AUTOSAR XML (schema 4-2-2)
package /STELLANTIS/EPT/ASWCs
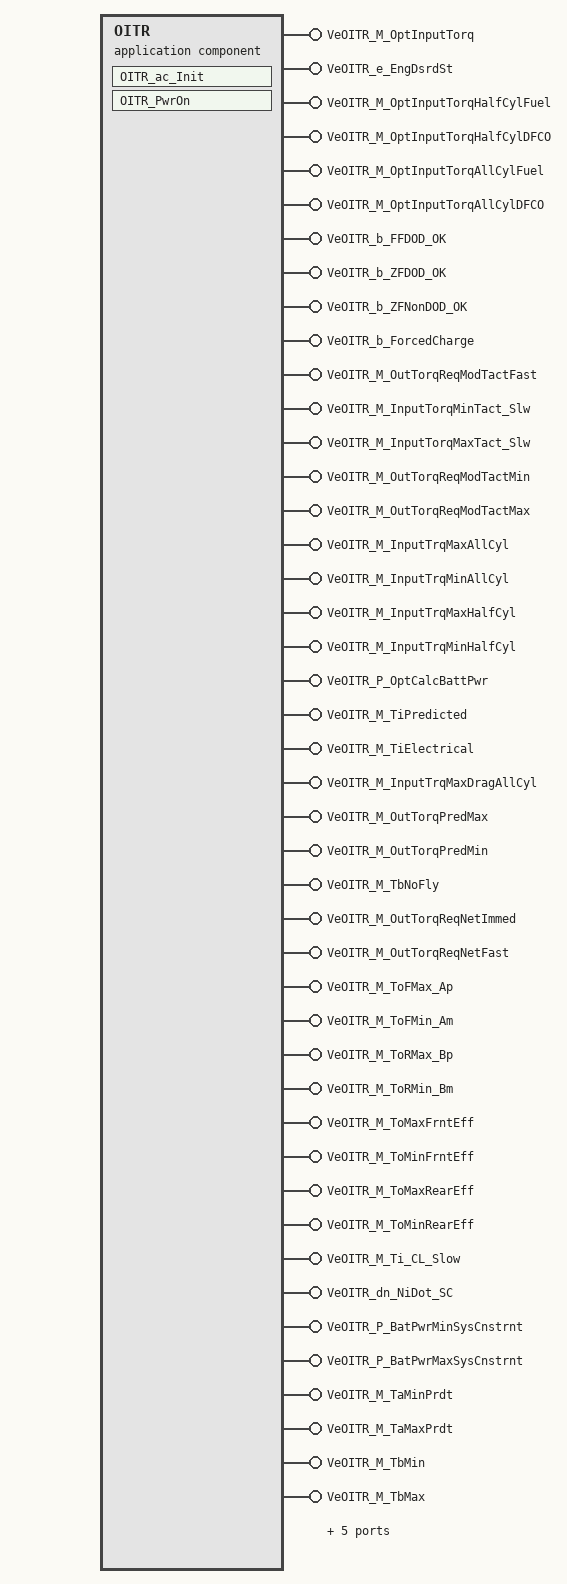
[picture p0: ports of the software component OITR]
  application sw component type OITR
    49 x provide port:
      VeOITR_M_OptInputTorq: nonqueued-sender-com-spec{data-element=Value, init-value=0}, provided-interface=VeOITR_M_OptInputTorq
      VeOITR_e_EngDsrdSt: nonqueued-sender-com-spec{data-element=Value, init-value=CeOITR_e_NonDOD_FF}, provided-interface=VeOITR_e_EngDsrdSt
      VeOITR_M_OptInputTorqHalfCylFuel: nonqueued-sender-com-spec{data-element=Value, init-value=0}, provided-interface=VeOITR_M_OptInputTorqHalfCylFuel
      VeOITR_M_OptInputTorqHalfCylDFCO: nonqueued-sender-com-spec{data-element=Value, init-value=0}, provided-interface=VeOITR_M_OptInputTorqHalfCylDFCO
      VeOITR_M_OptInputTorqAllCylFuel: nonqueued-sender-com-spec{data-element=Value, init-value=0}, provided-interface=VeOITR_M_OptInputTorqAllCylFuel
      VeOITR_M_OptInputTorqAllCylDFCO: nonqueued-sender-com-spec{data-element=Value, init-value=0}, provided-interface=VeOITR_M_OptInputTorqAllCylDFCO
      VeOITR_b_FFDOD_OK: nonqueued-sender-com-spec{data-element=Value, init-value=0}, provided-interface=VeOITR_b_FFDOD_OK
      VeOITR_b_ZFDOD_OK: nonqueued-sender-com-spec{data-element=Value, init-value=0}, provided-interface=VeOITR_b_ZFDOD_OK
      VeOITR_b_ZFNonDOD_OK: nonqueued-sender-com-spec{data-element=Value, init-value=0}, provided-interface=VeOITR_b_ZFNonDOD_OK
      VeOITR_b_ForcedCharge: nonqueued-sender-com-spec{data-element=Value, init-value=0}, provided-interface=VeOITR_b_ForcedCharge
      VeOITR_M_OutTorqReqModTactFast: nonqueued-sender-com-spec{data-element=Value, init-value=0}, provided-interface=VeOITR_M_OutTorqReqModTactFast
      VeOITR_M_InputTorqMinTact_Slw: nonqueued-sender-com-spec{data-element=Value, init-value=0}, provided-interface=VeOITR_M_InputTorqMinTact_Slw
      VeOITR_M_InputTorqMaxTact_Slw: nonqueued-sender-com-spec{data-element=Value, init-value=0}, provided-interface=VeOITR_M_InputTorqMaxTact_Slw
      VeOITR_M_OutTorqReqModTactMin: nonqueued-sender-com-spec{data-element=Value, init-value=0}, provided-interface=VeOITR_M_OutTorqReqModTactMin
      VeOITR_M_OutTorqReqModTactMax: nonqueued-sender-com-spec{data-element=Value, init-value=0}, provided-interface=VeOITR_M_OutTorqReqModTactMax
      VeOITR_M_InputTrqMaxAllCyl: nonqueued-sender-com-spec{data-element=Value, init-value=0}, provided-interface=VeOITR_M_InputTrqMaxAllCyl
      VeOITR_M_InputTrqMinAllCyl: nonqueued-sender-com-spec{data-element=Value, init-value=0}, provided-interface=VeOITR_M_InputTrqMinAllCyl
      VeOITR_M_InputTrqMaxHalfCyl: nonqueued-sender-com-spec{data-element=Value, init-value=0}, provided-interface=VeOITR_M_InputTrqMaxHalfCyl
      VeOITR_M_InputTrqMinHalfCyl: nonqueued-sender-com-spec{data-element=Value, init-value=0}, provided-interface=VeOITR_M_InputTrqMinHalfCyl
      VeOITR_P_OptCalcBattPwr: nonqueued-sender-com-spec{data-element=Value, init-value=0}, provided-interface=VeOITR_P_OptCalcBattPwr
      VeOITR_M_TiPredicted: nonqueued-sender-com-spec{data-element=Value, init-value=0}, provided-interface=VeOITR_M_TiPredicted
      VeOITR_M_TiElectrical: nonqueued-sender-com-spec{data-element=Value, init-value=0}, provided-interface=VeOITR_M_TiElectrical
      VeOITR_M_InputTrqMaxDragAllCyl: nonqueued-sender-com-spec{data-element=Value, init-value=0}, provided-interface=VeOITR_M_InputTrqMaxDragAllCyl
      VeOITR_M_OutTorqPredMax: nonqueued-sender-com-spec{data-element=Value, init-value=0}, provided-interface=VeOITR_M_OutTorqPredMax
      VeOITR_M_OutTorqPredMin: nonqueued-sender-com-spec{data-element=Value, init-value=0}, provided-interface=VeOITR_M_OutTorqPredMin
      VeOITR_M_TbNoFly: nonqueued-sender-com-spec{data-element=Value, init-value=0}, provided-interface=VeOITR_M_TbNoFly
      VeOITR_M_OutTorqReqNetImmed: nonqueued-sender-com-spec{data-element=Value, init-value=0}, provided-interface=VeOITR_M_OutTorqReqNetImmed
      VeOITR_M_OutTorqReqNetFast: nonqueued-sender-com-spec{data-element=Value, init-value=0}, provided-interface=VeOITR_M_OutTorqReqNetFast
      VeOITR_M_ToFMax_Ap: nonqueued-sender-com-spec{data-element=Value, init-value=0}, provided-interface=VeOITR_M_ToFMax_Ap
      VeOITR_M_ToFMin_Am: nonqueued-sender-com-spec{data-element=Value, init-value=0}, provided-interface=VeOITR_M_ToFMin_Am
      VeOITR_M_ToRMax_Bp: nonqueued-sender-com-spec{data-element=Value, init-value=0}, provided-interface=VeOITR_M_ToRMax_Bp
      VeOITR_M_ToRMin_Bm: nonqueued-sender-com-spec{data-element=Value, init-value=0}, provided-interface=VeOITR_M_ToRMin_Bm
      VeOITR_M_ToMaxFrntEff: nonqueued-sender-com-spec{data-element=Value, init-value=0}, provided-interface=VeOITR_M_ToMaxFrntEff
      VeOITR_M_ToMinFrntEff: nonqueued-sender-com-spec{data-element=Value, init-value=0}, provided-interface=VeOITR_M_ToMinFrntEff
      VeOITR_M_ToMaxRearEff: nonqueued-sender-com-spec{data-element=Value, init-value=0}, provided-interface=VeOITR_M_ToMaxRearEff
      VeOITR_M_ToMinRearEff: nonqueued-sender-com-spec{data-element=Value, init-value=0}, provided-interface=VeOITR_M_ToMinRearEff
      VeOITR_M_Ti_CL_Slow: nonqueued-sender-com-spec{data-element=Value, init-value=0}, provided-interface=VeOITR_M_Ti_CL_Slow
      VeOITR_dn_NiDot_SC: nonqueued-sender-com-spec{data-element=Value, init-value=0}, provided-interface=VeOITR_dn_NiDot_SC
      VeOITR_P_BatPwrMinSysCnstrnt: nonqueued-sender-com-spec{data-element=Value, init-value=0}, provided-interface=VeOITR_P_BatPwrMinSysCnstrnt
      VeOITR_P_BatPwrMaxSysCnstrnt: nonqueued-sender-com-spec{data-element=Value, init-value=0}, provided-interface=VeOITR_P_BatPwrMaxSysCnstrnt
      VeOITR_M_TaMinPrdt: nonqueued-sender-com-spec{data-element=Value, init-value=0}, provided-interface=VeOITR_M_TaMinPrdt
      VeOITR_M_TaMaxPrdt: nonqueued-sender-com-spec{data-element=Value, init-value=0}, provided-interface=VeOITR_M_TaMaxPrdt
      VeOITR_M_TbMin: nonqueued-sender-com-spec{data-element=Value, init-value=0}, provided-interface=VeOITR_M_TbMin
      VeOITR_M_TbMax: nonqueued-sender-com-spec{data-element=Value, init-value=0}, provided-interface=VeOITR_M_TbMax
      VeOITR_M_TcMin: nonqueued-sender-com-spec{data-element=Value, init-value=0}, provided-interface=VeOITR_M_TcMin
      VeOITR_M_TcMax: nonqueued-sender-com-spec{data-element=Value, init-value=0}, provided-interface=VeOITR_M_TcMax
      VeOITR_M_InputTrqMinArb: nonqueued-sender-com-spec{data-element=Value, init-value=0}, provided-interface=VeOITR_M_InputTrqMinArb
      VeOITR_M_InputTorqMinTact_Fst: nonqueued-sender-com-spec{data-element=Value, init-value=0}, provided-interface=VeOITR_M_InputTorqMinTact_Fst
      VeOITR_M_InputTorqMaxTact_Fst: nonqueued-sender-com-spec{data-element=Value, init-value=0}, provided-interface=VeOITR_M_InputTorqMaxTact_Fst
    behavior IB_OITR: data-type-mapping=msADTtoIDTMapping, handle-termination-and-restart=NO-SUPPORT, included-data-type-set=data-type=[TeOPTR_e_OptType, TeTSXR_e_PrfrdComb]
      init event Event_OITR_ac_Init: start-on-event=OITR_ac_Init
      init event Event_PwrOn: start-on-event=OITR_PwrOn
      runnable OITR_ac_Init
        data-send-points:
          access OUT_VeOITR_e_EngDsrdSt_Value: accessed-variable=VeOITR_e_EngDsrdSt.Value
      runnable OITR_PwrOn
        data-send-points:
          49 x access:
            OUT_VeOITR_M_OptInputTorq_Value: accessed-variable=VeOITR_M_OptInputTorq.Value
            OUT_VeOITR_b_ZFNonDOD_OK_Value: accessed-variable=VeOITR_b_ZFNonDOD_OK.Value
            OUT_VeOITR_b_ZFDOD_OK_Value: accessed-variable=VeOITR_b_ZFDOD_OK.Value
            OUT_VeOITR_b_FFDOD_OK_Value: accessed-variable=VeOITR_b_FFDOD_OK.Value
            OUT_VeOITR_b_ForcedCharge_Value: accessed-variable=VeOITR_b_ForcedCharge.Value
            OUT_VeOITR_e_EngDsrdSt_Value: accessed-variable=VeOITR_e_EngDsrdSt.Value
            OUT_VeOITR_M_OptInputTorqHalfCylFuel_Value: accessed-variable=VeOITR_M_OptInputTorqHalfCylFuel.Value
            OUT_VeOITR_M_OptInputTorqHalfCylDFCO_Value: accessed-variable=VeOITR_M_OptInputTorqHalfCylDFCO.Value
            OUT_VeOITR_M_OptInputTorqAllCylFuel_Value: accessed-variable=VeOITR_M_OptInputTorqAllCylFuel.Value
            OUT_VeOITR_M_OptInputTorqAllCylDFCO_Value: accessed-variable=VeOITR_M_OptInputTorqAllCylDFCO.Value
            OUT_VeOITR_M_OutTorqReqModTactFast_Value: accessed-variable=VeOITR_M_OutTorqReqModTactFast.Value
            OUT_VeOITR_M_InputTorqMinTact_Slw_Value: accessed-variable=VeOITR_M_InputTorqMinTact_Slw.Value
            OUT_VeOITR_M_InputTorqMaxTact_Slw_Value: accessed-variable=VeOITR_M_InputTorqMaxTact_Slw.Value
            OUT_VeOITR_M_OutTorqReqModTactMin_Value: accessed-variable=VeOITR_M_OutTorqReqModTactMin.Value
            OUT_VeOITR_M_OutTorqReqModTactMax_Value: accessed-variable=VeOITR_M_OutTorqReqModTactMax.Value
            OUT_VeOITR_M_InputTrqMaxAllCyl_Value: accessed-variable=VeOITR_M_InputTrqMaxAllCyl.Value
            OUT_VeOITR_M_InputTrqMinAllCyl_Value: accessed-variable=VeOITR_M_InputTrqMinAllCyl.Value
            OUT_VeOITR_M_InputTrqMaxHalfCyl_Value: accessed-variable=VeOITR_M_InputTrqMaxHalfCyl.Value
            OUT_VeOITR_M_InputTrqMinHalfCyl_Value: accessed-variable=VeOITR_M_InputTrqMinHalfCyl.Value
            OUT_VeOITR_P_OptCalcBattPwr_Value: accessed-variable=VeOITR_P_OptCalcBattPwr.Value
            OUT_VeOITR_M_TiPredicted_Value: accessed-variable=VeOITR_M_TiPredicted.Value
            OUT_VeOITR_M_TiElectrical_Value: accessed-variable=VeOITR_M_TiElectrical.Value
            OUT_VeOITR_M_InputTrqMaxDragAllCyl_Value: accessed-variable=VeOITR_M_InputTrqMaxDragAllCyl.Value
            OUT_VeOITR_M_OutTorqPredMax_Value: accessed-variable=VeOITR_M_OutTorqPredMax.Value
            OUT_VeOITR_M_OutTorqPredMin_Value: accessed-variable=VeOITR_M_OutTorqPredMin.Value
            OUT_VeOITR_M_TbNoFly_Value: accessed-variable=VeOITR_M_TbNoFly.Value
            OUT_VeOITR_M_OutTorqReqNetImmed_Value: accessed-variable=VeOITR_M_OutTorqReqNetImmed.Value
            OUT_VeOITR_M_OutTorqReqNetFast_Value: accessed-variable=VeOITR_M_OutTorqReqNetFast.Value
            OUT_VeOITR_M_ToFMax_Ap_Value: accessed-variable=VeOITR_M_ToFMax_Ap.Value
            OUT_VeOITR_M_ToFMin_Am_Value: accessed-variable=VeOITR_M_ToFMin_Am.Value
            OUT_VeOITR_M_ToRMax_Bp_Value: accessed-variable=VeOITR_M_ToRMax_Bp.Value
            OUT_VeOITR_M_ToRMin_Bm_Value: accessed-variable=VeOITR_M_ToRMin_Bm.Value
            OUT_VeOITR_M_ToMaxFrntEff_Value: accessed-variable=VeOITR_M_ToMaxFrntEff.Value
            OUT_VeOITR_M_ToMinFrntEff_Value: accessed-variable=VeOITR_M_ToMinFrntEff.Value
            OUT_VeOITR_M_ToMaxRearEff_Value: accessed-variable=VeOITR_M_ToMaxRearEff.Value
            OUT_VeOITR_M_ToMinRearEff_Value: accessed-variable=VeOITR_M_ToMinRearEff.Value
            OUT_VeOITR_M_Ti_CL_Slow_Value: accessed-variable=VeOITR_M_Ti_CL_Slow.Value
            OUT_VeOITR_dn_NiDot_SC_Value: accessed-variable=VeOITR_dn_NiDot_SC.Value
            OUT_VeOITR_P_BatPwrMinSysCnstrnt_Value: accessed-variable=VeOITR_P_BatPwrMinSysCnstrnt.Value
            OUT_VeOITR_P_BatPwrMaxSysCnstrnt_Value: accessed-variable=VeOITR_P_BatPwrMaxSysCnstrnt.Value
            OUT_VeOITR_M_TaMinPrdt_Value: accessed-variable=VeOITR_M_TaMinPrdt.Value
            OUT_VeOITR_M_TaMaxPrdt_Value: accessed-variable=VeOITR_M_TaMaxPrdt.Value
            OUT_VeOITR_M_TbMin_Value: accessed-variable=VeOITR_M_TbMin.Value
            OUT_VeOITR_M_TbMax_Value: accessed-variable=VeOITR_M_TbMax.Value
            OUT_VeOITR_M_TcMin_Value: accessed-variable=VeOITR_M_TcMin.Value
            OUT_VeOITR_M_TcMax_Value: accessed-variable=VeOITR_M_TcMax.Value
            OUT_VeOITR_M_InputTrqMinArb_Value: accessed-variable=VeOITR_M_InputTrqMinArb.Value
            OUT_VeOITR_M_InputTorqMinTact_Fst_Value: accessed-variable=VeOITR_M_InputTorqMinTact_Fst.Value
            OUT_VeOITR_M_InputTorqMaxTact_Fst_Value: accessed-variable=VeOITR_M_InputTorqMaxTact_Fst.Value
      18 x variation point proxy, all with category=CONDITION:
        Variant_HSCL_3Mot_Enbl: condition-access=0
        Variant_HSCL_BstConvEnbl: condition-access=0
        Variant_HSCL_SEMArbEnbl: condition-access=0
        Variant_HSCR_TorqueFloor_1: condition-access=0
        Variant_HSCR_UseAdherenceLim_1: condition-access=1
        Variant_OITR_BoostedSEMEnable: condition-access=0
        Variant_OITR_FUNC: condition-access=0
        Variant_OITR_MDSPathEnable: condition-access=0
        Variant_OITR_P1P2p5RattleMngmntEnable: condition-access=0
        Variant_OITR_TrqFloorLib_Enable: condition-access=0
        Variant_OPTL_3MtrEnbl: condition-access=0
        Variant_OPTL_ABOCase_BEV: condition-access=1
        Variant_OPTL_ABOCase_FullABO: condition-access=0
        Variant_OPTL_ABPtsEnbl: condition-access=1
        Variant_OPTL_EPtsEnbl: condition-access=1
        Variant_OPTL_HPtEnbl: condition-access=1
        Variant_OPTL_HPtEnbl_ToMinMax: condition-access=1
        Variant_OPTL_LegacyModeCnst: condition-access=1
